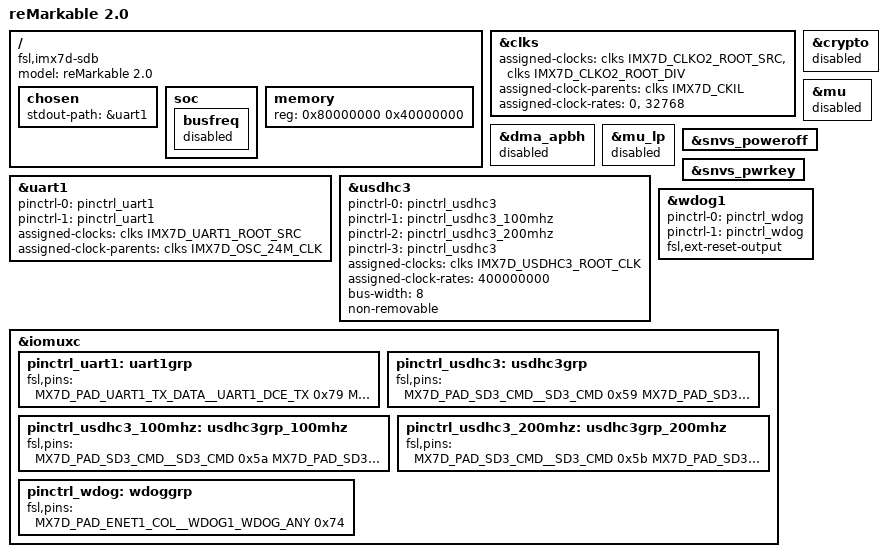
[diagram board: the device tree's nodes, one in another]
// SPDX-License-Identifier: GPL-2.0+ OR MIT
//
// Copyright (C) 2021 reMarkable AS - http://www.remarkable.com/

/dts-v1/;

#include "imx7d.dtsi"

/ {
	model = "reMarkable 2.0";
	compatible = "fsl,imx7d-sdb", "fsl,imx7d";

	/delete-node/ reserved-memory;

	chosen {
		stdout-path = &uart1;
	};

	soc {
		busfreq {
			status = "disabled";
		};
	};

	memory {
		reg = <0x80000000 0x40000000>;
	};
};

&clks {
	assigned-clocks = <&clks IMX7D_CLKO2_ROOT_SRC>,
			  <&clks IMX7D_CLKO2_ROOT_DIV>;
	assigned-clock-parents = <&clks IMX7D_CKIL>;
	assigned-clock-rates = <0>, <32768>;
};

&crypto {
	status = "disabled";
};

&dma_apbh {
	status = "disabled";
};

&mu {
	status = "disabled";
};

&mu_lp {
	status = "disabled";
};

&snvs_poweroff {
	status = "okay";
};

&snvs_pwrkey {
	status = "okay";
};

&uart1 {
	pinctrl-names = "default", "sleep";
	pinctrl-0 = <&pinctrl_uart1>;
	pinctrl-1 = <&pinctrl_uart1>;
	assigned-clocks = <&clks IMX7D_UART1_ROOT_SRC>;
	assigned-clock-parents = <&clks IMX7D_OSC_24M_CLK>;
	status = "okay";
};

&usdhc3 {
	pinctrl-names = "default", "state_100mhz", "state_200mhz", "sleep";
	pinctrl-0 = <&pinctrl_usdhc3>;
	pinctrl-1 = <&pinctrl_usdhc3_100mhz>;
	pinctrl-2 = <&pinctrl_usdhc3_200mhz>;
	pinctrl-3 = <&pinctrl_usdhc3>;
	assigned-clocks = <&clks IMX7D_USDHC3_ROOT_CLK>;
	assigned-clock-rates = <400000000>;
	bus-width = <8>;
	non-removable;
	status = "okay";
};

&wdog1 {
	pinctrl-names = "default", "sleep";
	pinctrl-0 = <&pinctrl_wdog>;
	pinctrl-1 = <&pinctrl_wdog>;
	fsl,ext-reset-output;
};

&iomuxc {
	pinctrl_uart1: uart1grp {
		fsl,pins = <
			MX7D_PAD_UART1_TX_DATA__UART1_DCE_TX	0x79
			MX7D_PAD_UART1_RX_DATA__UART1_DCE_RX	0x79
		>;
	};


	pinctrl_usdhc3: usdhc3grp {
		fsl,pins = <
			MX7D_PAD_SD3_CMD__SD3_CMD		0x59
			MX7D_PAD_SD3_CLK__SD3_CLK		0x19
			MX7D_PAD_SD3_DATA0__SD3_DATA0		0x59
			MX7D_PAD_SD3_DATA1__SD3_DATA1		0x59
			MX7D_PAD_SD3_DATA2__SD3_DATA2		0x59
			MX7D_PAD_SD3_DATA3__SD3_DATA3		0x59
			MX7D_PAD_SD3_DATA4__SD3_DATA4		0x59
			MX7D_PAD_SD3_DATA5__SD3_DATA5		0x59
			MX7D_PAD_SD3_DATA6__SD3_DATA6		0x59
			MX7D_PAD_SD3_DATA7__SD3_DATA7		0x59
			MX7D_PAD_SD3_STROBE__SD3_STROBE		0x19
		>;
	};

	pinctrl_usdhc3_100mhz: usdhc3grp_100mhz {
		fsl,pins = <
			MX7D_PAD_SD3_CMD__SD3_CMD		0x5a
			MX7D_PAD_SD3_CLK__SD3_CLK		0x1a
			MX7D_PAD_SD3_DATA0__SD3_DATA0		0x5a
			MX7D_PAD_SD3_DATA1__SD3_DATA1		0x5a
			MX7D_PAD_SD3_DATA2__SD3_DATA2		0x5a
			MX7D_PAD_SD3_DATA3__SD3_DATA3		0x5a
			MX7D_PAD_SD3_DATA4__SD3_DATA4		0x5a
			MX7D_PAD_SD3_DATA5__SD3_DATA5		0x5a
			MX7D_PAD_SD3_DATA6__SD3_DATA6		0x5a
			MX7D_PAD_SD3_DATA7__SD3_DATA7		0x5a
			MX7D_PAD_SD3_STROBE__SD3_STROBE		0x1a
		>;
	};

	pinctrl_usdhc3_200mhz: usdhc3grp_200mhz {
		fsl,pins = <
			MX7D_PAD_SD3_CMD__SD3_CMD		0x5b
			MX7D_PAD_SD3_CLK__SD3_CLK		0x1b
			MX7D_PAD_SD3_DATA0__SD3_DATA0		0x5b
			MX7D_PAD_SD3_DATA1__SD3_DATA1		0x5b
			MX7D_PAD_SD3_DATA2__SD3_DATA2		0x5b
			MX7D_PAD_SD3_DATA3__SD3_DATA3		0x5b
			MX7D_PAD_SD3_DATA4__SD3_DATA4		0x5b
			MX7D_PAD_SD3_DATA5__SD3_DATA5		0x5b
			MX7D_PAD_SD3_DATA6__SD3_DATA6		0x5b
			MX7D_PAD_SD3_DATA7__SD3_DATA7		0x5b
			MX7D_PAD_SD3_STROBE__SD3_STROBE		0x1b
		>;
	};

	pinctrl_wdog: wdoggrp {
		fsl,pins = <
			MX7D_PAD_ENET1_COL__WDOG1_WDOG_ANY	0x74
		>;
	};
};
